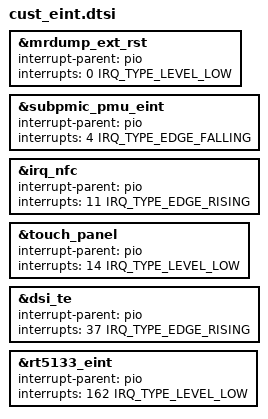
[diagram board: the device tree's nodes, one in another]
/*
 * Generated by MTK SP DrvGen Version: 3.5.160809 for MT6877.
 * 2023-12-12 19:21:58
 * Do Not Modify The File.
 * Copyright Mediatek Inc. (c) 2016.
*/

/*************************
 * EINT DTSI File
*************************/

#include <dt-bindings/interrupt-controller/irq.h>
#include <dt-bindings/interrupt-controller/arm-gic.h>

&mrdump_ext_rst {
	interrupt-parent = <&pio>;
	interrupts = <0 IRQ_TYPE_LEVEL_LOW>;
	status = "okay";
};

&subpmic_pmu_eint {
	interrupt-parent = <&pio>;
	interrupts = <4 IRQ_TYPE_EDGE_FALLING>;
	status = "okay";
};

&irq_nfc {
	interrupt-parent = <&pio>;
	interrupts = <11 IRQ_TYPE_EDGE_RISING>;
	status = "okay";
};

&touch_panel {
	interrupt-parent = <&pio>;
	interrupts = <14 IRQ_TYPE_LEVEL_LOW>;
	status = "okay";
};

&dsi_te {
	interrupt-parent = <&pio>;
	interrupts = <37 IRQ_TYPE_EDGE_RISING>;
	status = "okay";
};

&rt5133_eint {
	interrupt-parent = <&pio>;
	interrupts = <162 IRQ_TYPE_LEVEL_LOW>;
	status = "okay";
};

